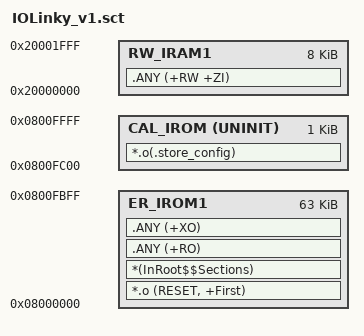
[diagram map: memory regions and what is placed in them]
; *************************************************************
; *** Scatter-Loading Description File generated by uVision ***
; *************************************************************

LR_IROM1 0x08000000 0x0000FC00  {    ; load region size_region
  ER_IROM1 0x08000000 0x0000FC00  {  ; load address = execution address
   *.o (RESET, +First)
   *(InRoot$$Sections)
   .ANY (+RO)
   .ANY (+XO)
  }
  
  RW_IRAM1 0x20000000 0x00002000  {  ; RW data
   .ANY (+RW +ZI)
  }
}

LR_ROM2 0x0800FC00 0x00000400{
  CAL_IROM 0x0800FC00 UNINIT 0x00000400{ ; Store ADC calibration and User congit data
	*.o(.store_config)
  }
}

